# STM32F103T6U6 register map
File version: 1.0
STM32F103C4T6,STM32F103C6T6,STM32F103C6U6,STM32F103R4H6,STM32F103R4T6,STM32F103R6H6,STM32F103R6T6,STM32F103T4U6,STM32F103T6U6
Registers are 32-bit, access not given, reset 0x0 unless marked. A register's access mark holds for its fields unless they carry their own. Offsets are from the block's base; lines under a group give offsets from that group; [hi:lo] are bit positions; {n}, {i} and the like mark numbered series; 'fields as' and 'values as' point back to an identical list; <NAME> marks a mode.

## Memory map
0x1FFFF800 OB
0x40000000 TIM2
0x40000400 TIM3
0x40002800 RTC
0x40002C00 WWDG
0x40003000 IWDG
0x40004400 USART2
0x40005400 I2C1
0x40005C00 USB
0x40006400 CAN1
0x40006C00 BKP
0x40007000 PWR
0x40010000 AFIO
0x40010400 EXTI
0x40010800 GPIOA
0x40010C00 GPIOB
0x40011000 GPIOC
0x40011400 GPIOD
0x40012400 ADC1
0x40012400 ADC12_COMMON
0x40012800 ADC2
0x40012C00 TIM1
0x40013000 SPI1
0x40013800 USART1
0x40020000 DMA1
0x40021000 RCC
0x40022000 FLASH
0x40023000 CRC
0xE0042000 DBGMCU

## OB
Base 0x1FFFF800
0x00 RDP 16-bit
0x02 USER 16-bit
0x04 Data0 16-bit
0x06 Data1 16-bit
{0x8+2i} WRP{i} 16-bit (i=0..3)

## TIM2
Base 0x40000000
Same registers: TIM3 0x40000400, TIM1 0x40012C00
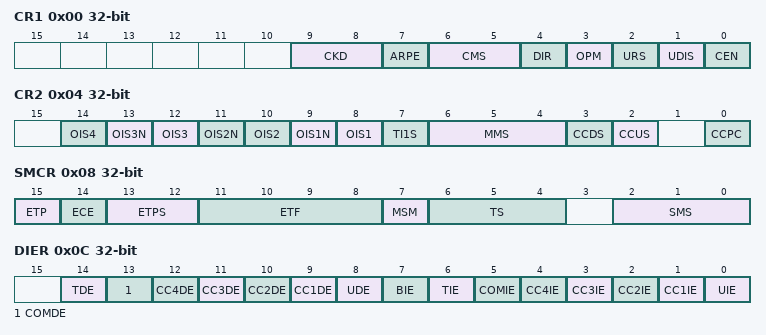
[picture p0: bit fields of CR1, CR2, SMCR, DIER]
0x00 CR1
  [9:8] CKD, [7] ARPE, [6:5] CMS, [4] DIR, [3] OPM, [2] URS, [1] UDIS, [0] CEN
0x04 CR2
  [2n+6] OIS{n} (n=1..4), [13] OIS3N, [11] OIS2N, [9] OIS1N, [7] TI1S, [6:4] MMS, [3] CCDS, [2] CCUS, [0] CCPC
0x08 SMCR
  [15] ETP, [14] ECE, [13:12] ETPS, [11:8] ETF, [7] MSM, [6:4] TS, [2:0] SMS
0x0C DIER
  [14] TDE, [13] COMDE, [n+8] CC{n}DE (n=1..4), [8] UDE, [7] BIE, [6] TIE, [5] COMIE, [n] CC{n}IE (n=1..4), [0] UIE
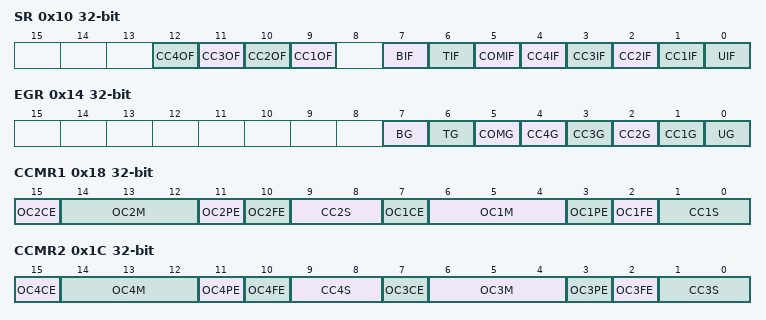
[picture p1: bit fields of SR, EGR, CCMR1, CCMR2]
0x10 SR
  [n+8] CC{n}OF (n=1..4), [7] BIF, [6] TIF, [5] COMIF, [n] CC{n}IF (n=1..4), [0] UIF
0x14 EGR
  [7] BG, [6] TG, [5] COMG, [n] CC{n}G (n=1..4), [0] UG
0x18 CCMR1
  [15] OC2CE, [14:12] OC2M, [11] OC2PE, [10] OC2FE, [9:8] CC2S, [7] OC1CE, [6:4] OC1M, [3] OC1PE, [2] OC1FE, [1:0] CC1S
0x1C CCMR2
  [15] OC4CE, [14:12] OC4M, [11] OC4PE, [10] OC4FE, [9:8] CC4S, [7] OC3CE, [6:4] OC3M, [3] OC3PE, [2] OC3FE, [1:0] CC3S
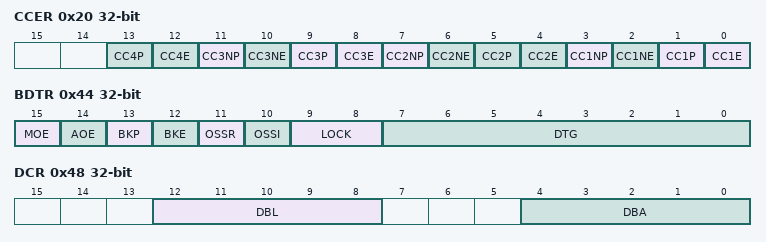
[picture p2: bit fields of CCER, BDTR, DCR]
0x20 CCER
  [4n-3] CC{n}P (n=1..4), [4n-4] CC{n}E (n=1..4), [11] CC3NP, [10] CC3NE, [7] CC2NP, [6] CC2NE, [3] CC1NP, [2] CC1NE
0x24 CNT
0x28 PSC
  [15:0] PSC
0x2C ARR
0x30 RCR
  [7:0] REP
{0x30+4i} CCR{i} (i=1..4)
  [15:0] CCR{i}
0x44 BDTR
  [15] MOE, [14] AOE, [13] BKP, [12] BKE, [11] OSSR, [10] OSSI, [9:8] LOCK, [7:0] DTG
0x48 DCR
  [12:8] DBL, [4:0] DBA
0x4C DMAR
  [15:0] DMAB
0x50 OR

## RTC
Base 0x40002800
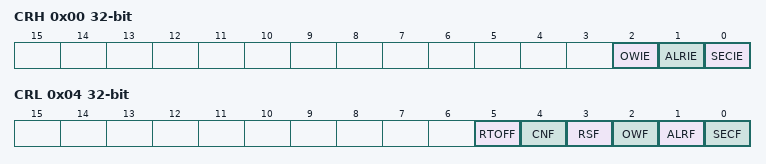
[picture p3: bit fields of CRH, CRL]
0x00 CRH
  [2] OWIE, [1] ALRIE, [0] SECIE
0x04 CRL
  [5] RTOFF, [4] CNF, [3] RSF, [2] OWF, [1] ALRF, [0] SECF
0x08 PRLH
  [3:0] PRL
0x0C PRLL
  [15:0] PRL
0x10 DIVH
  [3:0] RTC_DIV
0x14 DIVL
  [15:0] RTC_DIV
0x18 CNTH
  [15:0] RTC_CNT
0x1C CNTL
  [15:0] RTC_CNT
0x20 ALRH
  [15:0] RTC_ALR
0x24 ALRL
  [15:0] RTC_ALR

## WWDG
Base 0x40002C00
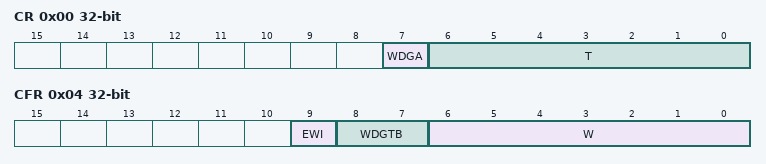
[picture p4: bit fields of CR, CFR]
0x00 CR
  [7] WDGA, [6:0] T
0x04 CFR
  [9] EWI, [8:7] WDGTB, [6:0] W
0x08 SR
  [0] EWIF

## IWDG
Base 0x40003000
0x00 KR
  [15:0] KEY
0x04 PR
  [2:0] PR
0x08 RLR
  [11:0] RL
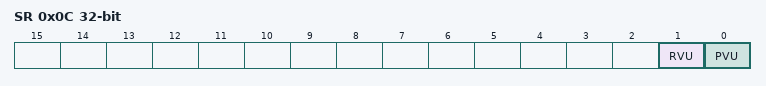
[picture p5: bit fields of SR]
0x0C SR
  [1] RVU, [0] PVU

## USART2
Base 0x40004400
Same registers: USART1 0x40013800
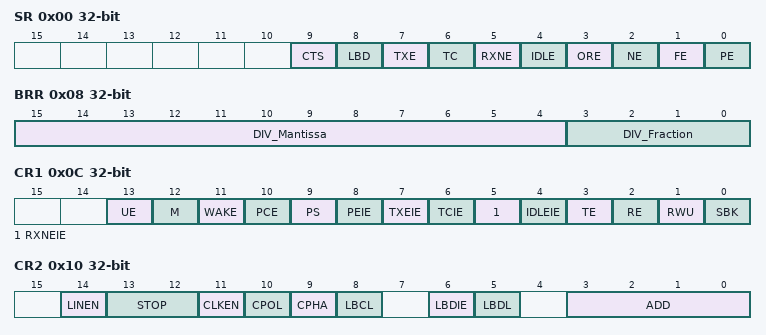
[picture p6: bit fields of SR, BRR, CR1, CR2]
0x00 SR
  [9] CTS, [8] LBD, [7] TXE, [6] TC, [5] RXNE, [4] IDLE, [3] ORE, [2] NE, [1] FE, [0] PE
0x04 DR
  [8:0] DR
0x08 BRR
  [15:4] DIV_Mantissa, [3:0] DIV_Fraction
0x0C CR1
  [13] UE, [12] M, [11] WAKE, [10] PCE, [9] PS, [8] PEIE, [7] TXEIE, [6] TCIE, [5] RXNEIE, [4] IDLEIE, [3] TE, [2] RE, [1] RWU, [0] SBK
0x10 CR2
  [14] LINEN, [13:12] STOP, [11] CLKEN, [10] CPOL, [9] CPHA, [8] LBCL, [6] LBDIE, [5] LBDL, [3:0] ADD
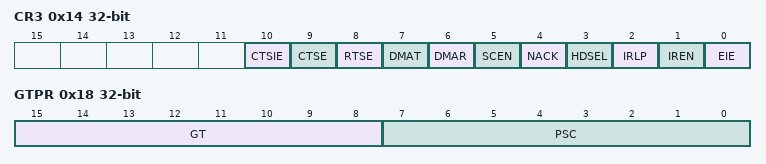
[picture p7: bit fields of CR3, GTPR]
0x14 CR3
  [10] CTSIE, [9] CTSE, [8] RTSE, [7] DMAT, [6] DMAR, [5] SCEN, [4] NACK, [3] HDSEL, [2] IRLP, [1] IREN, [0] EIE
0x18 GTPR
  [15:8] GT, [7:0] PSC

## I2C1
Base 0x40005400
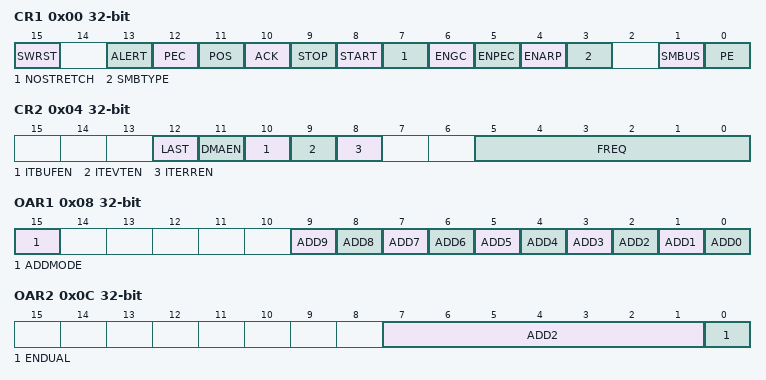
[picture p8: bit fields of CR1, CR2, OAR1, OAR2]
0x00 CR1
  [15] SWRST, [13] ALERT, [12] PEC, [11] POS, [10] ACK, [9] STOP, [8] START, [7] NOSTRETCH, [6] ENGC, [5] ENPEC, [4] ENARP, [3] SMBTYPE, [1] SMBUS, [0] PE
0x04 CR2
  [12] LAST, [11] DMAEN, [10] ITBUFEN, [9] ITEVTEN, [8] ITERREN, [5:0] FREQ
0x08 OAR1
  [15] ADDMODE, [n] ADD{n} (n=0..9)
0x0C OAR2
  [7:1] ADD2, [0] ENDUAL
0x10 DR
  [7:0] DR
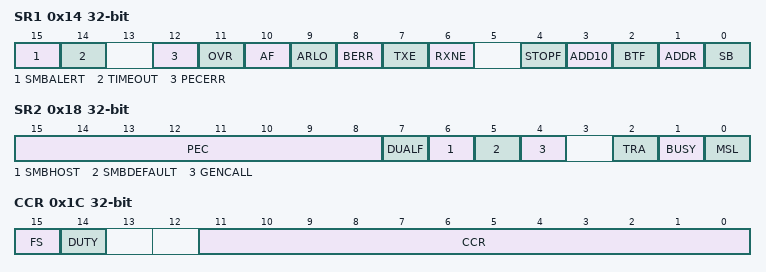
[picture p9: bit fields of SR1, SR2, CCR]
0x14 SR1
  [15] SMBALERT, [14] TIMEOUT, [12] PECERR, [11] OVR, [10] AF, [9] ARLO, [8] BERR, [7] TXE, [6] RXNE, [4] STOPF, [3] ADD10, [2] BTF, [1] ADDR, [0] SB
0x18 SR2
  [15:8] PEC, [7] DUALF, [6] SMBHOST, [5] SMBDEFAULT, [4] GENCALL, [2] TRA, [1] BUSY, [0] MSL
0x1C CCR
  [15] FS, [14] DUTY, [11:0] CCR
0x20 TRISE
  [5:0] TRISE
